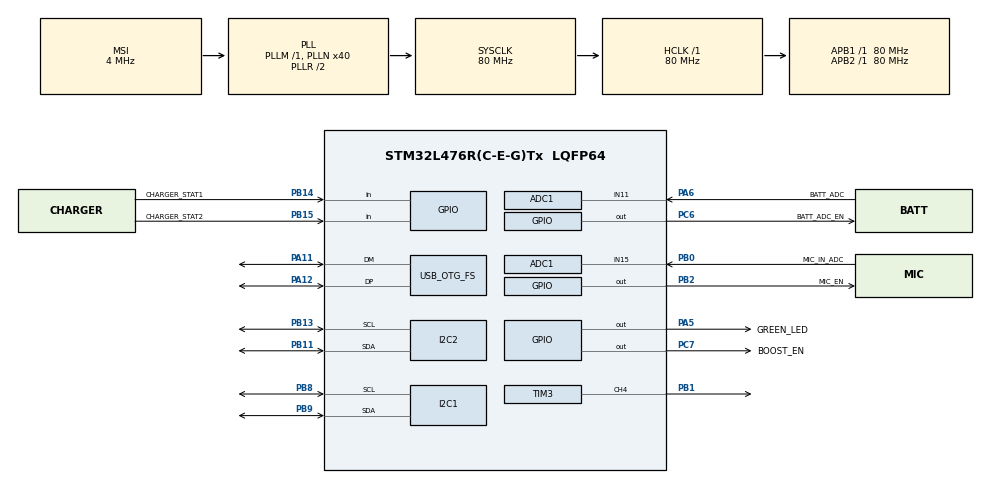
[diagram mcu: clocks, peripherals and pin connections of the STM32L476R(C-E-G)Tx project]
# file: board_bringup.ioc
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Mcu.Family=STM32L4
USB_DEVICE.CLASS_NAME_FS=CDC
RCC.CortexFreq_Value=80000000
PB14.GPIO_Label=CHARGER_STAT1
Dma.TIM3_CH4/UP.0.Mode=DMA_NORMAL
I2C2.Timing=0x10909CEC
PC6.GPIO_Label=BATT_ADC_EN
PA11.Mode=Device_Only
PA6.GPIO_Label=BATT_ADC
PB0.GPIO_Label=MIC_IN_ADC
PB11.Signal=I2C2_SDA
PB13.Signal=I2C2_SCL
PB15.Signal=GPIO_Input
TIM3.Channel-PWM\ Generation4\ CH4=TIM_CHANNEL_4
RCC.SYSCLKSource=RCC_SYSCLKSOURCE_PLLCLK
ProjectManager.StackSize=0x400
NVIC.DMA1_Channel3_IRQn=true\:0\:0\:false\:false\:true\:false\:true
PA14\ (JTCK-SWCLK).Signal=SYS_JTCK-SWCLK
USB_DEVICE.MANUFACTURER_STRING=LIGHT CUBE
PA12.Signal=USB_OTG_FS_DP
RCC.HCLKFreq_Value=80000000
ADC1.Offset-1\#ChannelRegularConversion=0
RCC.APB2TimFreq_Value=80000000
PC7.Signal=GPIO_Output
RCC.AHBFreq_Value=80000000
RCC.HSE_VALUE=8000000
PB2.Signal=GPIO_Output
SH.ADCx_IN15.0=ADC1_IN15,IN15-Single-Ended
PA5.GPIO_PuPd=GPIO_PULLUP
PC7.PinState=GPIO_PIN_SET
Mcu.Package=LQFP64
PB9.Signal=I2C1_SDA
PB1.Signal=S_TIM3_CH4
PA6.Signal=ADCx_IN11
Dma.TIM3_CH4/UP.0.Priority=DMA_PRIORITY_LOW
NVIC.OTG_FS_IRQn=true\:0\:0\:false\:false\:true\:true\:true
USB_OTG_FS.VirtualMode=Device_Only
ADC1.OffsetNumber-1\#ChannelRegularConversion=ADC_OFFSET_4
Dma.TIM3_CH4/UP.0.Direction=DMA_MEMORY_TO_PERIPH
RCC.APB1TimFreq_Value=80000000
PB13.Mode=I2C
PA13\ (JTMS-SWDIO).Signal=SYS_JTMS-SWDIO
Dma.Request0=TIM3_CH4/UP
Dma.TIM3_CH4/UP.0.PeriphDataAlignment=DMA_PDATAALIGN_HALFWORD
RCC.PLLSAI1N=24
RCC.MSI_VALUE=4000000
PA14\ (JTCK-SWCLK).Mode=Serial_Wire
I2C1.Speed=100
USB_DEVICE.VirtualModeFS=Cdc_FS
PC6.Signal=GPIO_Output
PB11.Mode=I2C
ProjectManager.TargetToolchain=Makefile
VP_USB_DEVICE_VS_USB_DEVICE_CDC_FS.Mode=CDC_FS
PB9.Mode=I2C
ADC1.Channel-1\#ChannelRegularConversion=ADC_CHANNEL_11
I2C1.Timing=0x10909CEC
Dma.TIM3_CH4/UP.0.Instance=DMA1_Channel3
RCC.USBFreq_Value=48000000
RCC.LSE_VALUE=32768
PB14.Signal=GPIO_Input
PA5.Signal=GPIO_Output
board=custom
RCC.VCOOutputFreq_Value=160000000
RCC.APB2Freq_Value=80000000
SH.ADCx_IN11.0=ADC1_IN11,IN11-Single-Ended
PB15.GPIO_Label=CHARGER_STAT2
RCC.ADCFreq_Value=48000000
Dma.TIM3_CH4/UP.0.MemInc=DMA_MINC_ENABLE
Mcu.Name=STM32L476R(C-E-G)Tx
PC7.GPIO_Label=BOOST_EN
PA13\ (JTMS-SWDIO).Mode=Serial_Wire
ADC1.SamplingTime-1\#ChannelRegularConversion=ADC_SAMPLETIME_24CYCLES_5
RCC.SYSCLKFreq_VALUE=80000000
ADC1.master=1
PA12.Mode=Device_Only
PA5.GPIO_Label=GREEN_LED
ADC1.Rank-1\#ChannelRegularConversion=1
PA11.Signal=USB_OTG_FS_DM
PB2.GPIO_Label=MIC_EN
ProjectManager.HeapSize=0x200
Dma.TIM3_CH4/UP.0.MemDataAlignment=DMA_MDATAALIGN_BYTE
RCC.HSI_VALUE=16000000
NVIC.PriorityGroup=NVIC_PRIORITYGROUP_4
ADC1.NbrOfConversionFlag=1
RCC.PLLN=40
PB8.Mode=I2C
PB8.Signal=I2C1_SCL
RCC.APB1Freq_Value=80000000
PB0.Signal=ADCx_IN15
USB_DEVICE.VirtualMode=Cdc
Dma.TIM3_CH4/UP.0.PeriphInc=DMA_PINC_DISABLE
SH.S_TIM3_CH4.0=TIM3_CH4,PWM Generation4 CH4

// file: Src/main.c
/* USER CODE BEGIN Header */
/**
  ******************************************************************************
  * @file           : main.c
  * @brief          : Main program body
  ******************************************************************************
  * @attention
  *
  * <h2><center>&copy; Copyright (c) 2020 STMicroelectronics.
  * All rights reserved.</center></h2>
  *
  * This software component is licensed by ST under BSD 3-Clause license,
  * the "License"; You may not use this file except in compliance with the
  * License. You may obtain a copy of the License at:
  *                        opensource.org/licenses/BSD-3-Clause
  *
  ******************************************************************************
  */
/* USER CODE END Header */

#include "main.h"
#include "adc.h"
#include "dma.h"
#include "i2c.h"
#include "tim.h"
#include "usb_device.h"
#include "gpio.h"

/* USER CODE BEGIN Includes */
#include <string.h>
/* USER CODE END Includes */

void SystemClock_Config(void);

int main(void)
{

  /* MCU Configuration--------------------------------------------------------*/

  /* Reset of all peripherals, Initializes the Flash interface and the Systick. */
  HAL_Init();

  /* Configure the system clock */
  SystemClock_Config();

  /* Initialize all configured peripherals */
  MX_GPIO_Init();
  MX_DMA_Init();
  MX_ADC1_Init();
  MX_I2C1_Init();
  MX_I2C2_Init();
  MX_TIM3_Init();
  MX_USB_DEVICE_Init();
  /* USER CODE BEGIN 2 */
  /*AddrLEDManager_Init();*/
  /*AddrLEDManager_SanityTest();*/
  /*AddrLEDManager_RefreshTimerStart();*/
  /* USER CODE END 2 */

  /* Infinite loop */
  while (1)
  {

  }
}

void SystemClock_Config(void)
{
  RCC_OscInitTypeDef RCC_OscInitStruct = {0};
  RCC_ClkInitTypeDef RCC_ClkInitStruct = {0};
  RCC_PeriphCLKInitTypeDef PeriphClkInit = {0};

  /** Initializes the CPU, AHB and APB busses clocks
  */
  RCC_OscInitStruct.OscillatorType = RCC_OSCILLATORTYPE_MSI;
  RCC_OscInitStruct.MSIState = RCC_MSI_ON;
  RCC_OscInitStruct.MSICalibrationValue = 0;
  RCC_OscInitStruct.MSIClockRange = RCC_MSIRANGE_6;
  RCC_OscInitStruct.PLL.PLLState = RCC_PLL_ON;
  RCC_OscInitStruct.PLL.PLLSource = RCC_PLLSOURCE_MSI;
  RCC_OscInitStruct.PLL.PLLM = 1;
  RCC_OscInitStruct.PLL.PLLN = 40;
  RCC_OscInitStruct.PLL.PLLP = RCC_PLLP_DIV7;
  RCC_OscInitStruct.PLL.PLLQ = RCC_PLLQ_DIV2;
  RCC_OscInitStruct.PLL.PLLR = RCC_PLLR_DIV2;
  if (HAL_RCC_OscConfig(&RCC_OscInitStruct) != HAL_OK)
  {
    Error_Handler();
  }
  /** Initializes the CPU, AHB and APB busses clocks
  */
  RCC_ClkInitStruct.ClockType = RCC_CLOCKTYPE_HCLK|RCC_CLOCKTYPE_SYSCLK
                              |RCC_CLOCKTYPE_PCLK1|RCC_CLOCKTYPE_PCLK2;
  RCC_ClkInitStruct.SYSCLKSource = RCC_SYSCLKSOURCE_PLLCLK;
  RCC_ClkInitStruct.AHBCLKDivider = RCC_SYSCLK_DIV1;
  RCC_ClkInitStruct.APB1CLKDivider = RCC_HCLK_DIV1;
  RCC_ClkInitStruct.APB2CLKDivider = RCC_HCLK_DIV1;

  if (HAL_RCC_ClockConfig(&RCC_ClkInitStruct, FLASH_LATENCY_4) != HAL_OK)
  {
    Error_Handler();
  }
  PeriphClkInit.PeriphClockSelection = RCC_PERIPHCLK_I2C1|RCC_PERIPHCLK_I2C2
                              |RCC_PERIPHCLK_USB|RCC_PERIPHCLK_ADC;
  PeriphClkInit.I2c1ClockSelection = RCC_I2C1CLKSOURCE_PCLK1;
  PeriphClkInit.I2c2ClockSelection = RCC_I2C2CLKSOURCE_PCLK1;
  PeriphClkInit.AdcClockSelection = RCC_ADCCLKSOURCE_PLLSAI1;
  PeriphClkInit.UsbClockSelection = RCC_USBCLKSOURCE_PLLSAI1;
  PeriphClkInit.PLLSAI1.PLLSAI1Source = RCC_PLLSOURCE_MSI;
  PeriphClkInit.PLLSAI1.PLLSAI1M = 1;
  PeriphClkInit.PLLSAI1.PLLSAI1N = 24;
  PeriphClkInit.PLLSAI1.PLLSAI1P = RCC_PLLP_DIV7;
  PeriphClkInit.PLLSAI1.PLLSAI1Q = RCC_PLLQ_DIV2;
  PeriphClkInit.PLLSAI1.PLLSAI1R = RCC_PLLR_DIV2;
  PeriphClkInit.PLLSAI1.PLLSAI1ClockOut = RCC_PLLSAI1_48M2CLK|RCC_PLLSAI1_ADC1CLK;
  if (HAL_RCCEx_PeriphCLKConfig(&PeriphClkInit) != HAL_OK)
  {
    Error_Handler();
  }
  /** Configure the main internal regulator output voltage
  */
  if (HAL_PWREx_ControlVoltageScaling(PWR_REGULATOR_VOLTAGE_SCALE1) != HAL_OK)
  {
    Error_Handler();
  }
}

void Error_Handler(void)
{
}

/************************ (C) COPYRIGHT STMicroelectronics *****END OF FILE****/
